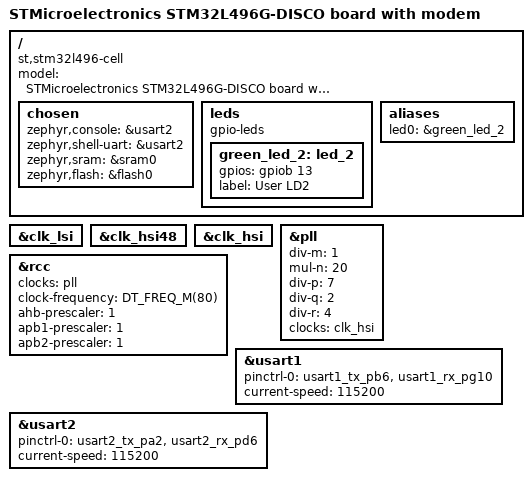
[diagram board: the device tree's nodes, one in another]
/*
 * Copyright (c) 2017 Linaro Limited
 *
 * SPDX-License-Identifier: Apache-2.0
 */

/* IOTEMBSYS1: This is the device tree file which defines the hardware on the board. */

/dts-v1/;
#include <st/l4/stm32l496Xg.dtsi>
#include <st/l4/stm32l496a(e-g)ix-pinctrl.dtsi>
#include "arduino_r3_connector.dtsi"

/ {
	model = "STMicroelectronics STM32L496G-DISCO board with modem";
	compatible = "st,stm32l496-cell";

	chosen {
		zephyr,console = &usart2;
		zephyr,shell-uart = &usart2;
		zephyr,sram = &sram0;
		zephyr,flash = &flash0;
	};

	leds {
		compatible = "gpio-leds";
		green_led_2: led_2 {
			gpios = <&gpiob 13 GPIO_ACTIVE_HIGH>;
			label = "User LD2";
		};
	};

	aliases {
		led0 = &green_led_2;
	};
};

&clk_lsi {
	status = "okay";
};

&clk_hsi48 {
	status = "okay";
};

&clk_hsi {
	status = "okay";
};

&pll {
	div-m = <1>;
	mul-n = <20>;
	div-p = <7>;
	div-q = <2>;
	div-r = <4>;
	clocks = <&clk_hsi>;
	status = "okay";
};

&rcc {
	clocks = <&pll>;
	clock-frequency = <DT_FREQ_M(80)>;
	ahb-prescaler = <1>;
	apb1-prescaler = <1>;
	apb2-prescaler = <1>;
};

&usart1 {
	pinctrl-0 = <&usart1_tx_pb6 &usart1_rx_pg10>;
	pinctrl-names = "default";
	current-speed = <115200>;
	status = "okay";
};

&usart2 {
	pinctrl-0 = <&usart2_tx_pa2 &usart2_rx_pd6>;
	pinctrl-names = "default";
	current-speed = <115200>;
	status = "okay";
};
